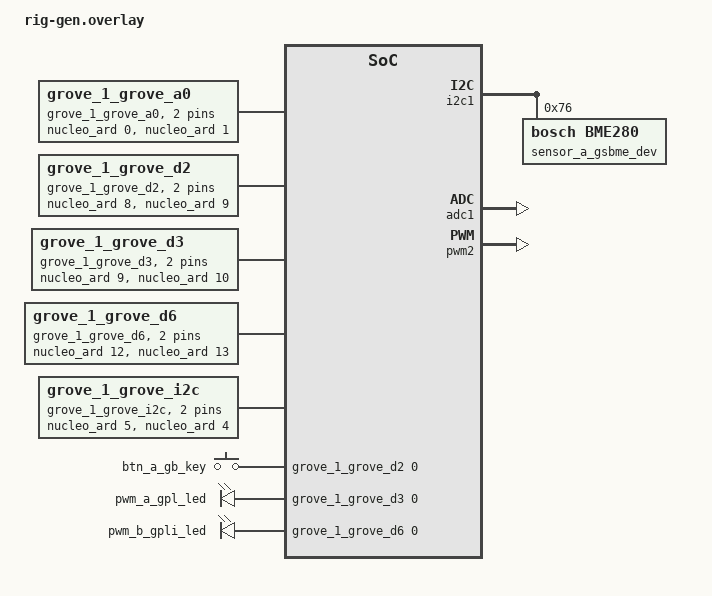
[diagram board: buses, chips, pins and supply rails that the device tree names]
#include "rig-gen-includes.dtsi"
/* generated by rigc — do not edit; the rig file is the source of truth
 * rig: nucleo_grove_farm  board: nucleo_f401re/stm32f401xe/rig
 */

/* carrier-exported sockets, synthesized as gpio-nexus nodes */
/ {
	grove_1_grove_a0: grove_1_grove_a0 {
		#gpio-cells = <2>;
		gpio-map-mask = <0xffffffff 0xffffffc0>;
		gpio-map-pass-thru = <0 0x3f>;
		gpio-map = <0 0 &nucleo_ard 0 0>,
			   <1 0 &nucleo_ard 1 0>;
		#io-channel-cells = <1>;
		io-channel-map-mask = <0xffffffff>;
		io-channel-map-pass-thru = <0x00000000>;
		io-channel-map = <0 &nucleo_ard 0>,
			   <1 &nucleo_ard 1>;
	};
	grove_1_grove_d2: grove_1_grove_d2 {
		#gpio-cells = <2>;
		gpio-map-mask = <0xffffffff 0xffffffc0>;
		gpio-map-pass-thru = <0 0x3f>;
		gpio-map = <0 0 &nucleo_ard 8 0>,
			   <1 0 &nucleo_ard 9 0>;
		#pwm-cells = <3>;
		pwm-map-mask = <0xffffffff 0x00000000 0x00000000>;
		pwm-map-pass-thru = <0x00000000 0xffffffff 0xffffffff>;
		pwm-map = <1 0 0 &nucleo_ard 9 0 0>;
	};
	grove_1_grove_d3: grove_1_grove_d3 {
		#gpio-cells = <2>;
		gpio-map-mask = <0xffffffff 0xffffffc0>;
		gpio-map-pass-thru = <0 0x3f>;
		gpio-map = <0 0 &nucleo_ard 9 0>,
			   <1 0 &nucleo_ard 10 0>;
		#pwm-cells = <3>;
		pwm-map-mask = <0xffffffff 0x00000000 0x00000000>;
		pwm-map-pass-thru = <0x00000000 0xffffffff 0xffffffff>;
		pwm-map = <0 0 0 &nucleo_ard 9 0 0>;
	};
	grove_1_grove_d6: grove_1_grove_d6 {
		#gpio-cells = <2>;
		gpio-map-mask = <0xffffffff 0xffffffc0>;
		gpio-map-pass-thru = <0 0x3f>;
		gpio-map = <0 0 &nucleo_ard 12 0>,
			   <1 0 &nucleo_ard 13 0>;
		#pwm-cells = <3>;
		pwm-map-mask = <0xffffffff 0x00000000 0x00000000>;
		pwm-map-pass-thru = <0x00000000 0xffffffff 0xffffffff>;
		pwm-map = <0 0 0 &nucleo_ard 12 0 0>,
			   <1 0 0 &nucleo_ard 13 0 0>;
	};
	grove_1_grove_i2c: grove_1_grove_i2c {
		#gpio-cells = <2>;
		gpio-map-mask = <0xffffffff 0xffffffc0>;
		gpio-map-pass-thru = <0 0x3f>;
		gpio-map = <0 0 &nucleo_ard 5 0>,
			   <1 0 &nucleo_ard 4 0>;
	};
};

&i2c1 {
	sensor_a_gsbme_dev: sensor@76 {
		compatible = "bosch,bme280";
		friendly-name = "Grove THP Sensor V1.0 (BME280)";
		reg = <0x76>;
		status = "okay";
	};
};

/ {
	gpio_keys: gpio_keys {
		compatible = "gpio-keys";
		btn_a_gb_key: btn_a_gb_key {
			label = "btn_a_gb_key";
			zephyr,code = <INPUT_KEY_0>;
			gpios = <&grove_1_grove_d2 0 0x20>;	/* SIG0 */
		};
	};
	pwm_leds: pwm_leds {
		compatible = "pwm-leds";
		pwm_a_gpl_led: pwm_a_gpl_led {
			label = "pwm_a_gpl_led";
			pwms = <&grove_1_grove_d3 0 20000000 0x0>;	/* SIG0 */
		};
		pwm_b_gpli_led: pwm_b_gpli_led {
			label = "pwm_b_gpli_led";
			pwms = <&grove_1_grove_d6 0 20000000 0x1>;	/* SIG0 */
		};
	};
};

/ {
	light_a {
		light_a_light: light {
			compatible = "vnd,light-sensor";
			io-channels = <&grove_1_grove_a0 0>;	/* SIG0 */
			status = "okay";
		};
	};
};

/* PWM/ADC: enable the resolved controllers; the pin-mux (pinctrl)
 * for each muxed pin is board-provided and must be applied —
 * stubbed here, see the config sheet. */
&adc1 { status = "okay"; };
&pwm2 { status = "okay"; };
